AUTOSAR XML
standard types defined: uint8, uint16, uint32
package /DataTypes
  mode declaration group EcuMode: initial-mode=/DataTypes/EcuMode/RUN
    mode RUN: value=0
    mode POST_RUN: value=1
package /Interfaces
  5 x sender receiver interface:
    VehicleSpeedIf
      data VehicleSpeed: type=/DataTypes/uint16, init-value=0
    AmbientLightIf
      data AmbientLight: type=/DataTypes/uint8, init-value=255
    HeadlightCmdIf
      data HeadlightCmd: type=/DataTypes/uint8, init-value=0
    HeadlightStatusIf
      data HeadlightStatus: type=/DataTypes/uint8, init-value=0
    OdometerDistanceIf
      data Distance: type=/DataTypes/uint32, init-value=0
  client server interface WheelSpeedIf
    operation GetWheelSpeed
      arg Raw: type=/DataTypes/uint16, direction=OUT
  client server interface LightHwIf
    operation SetHeadlight
      arg State: type=/DataTypes/uint8, direction=IN
  client server interface OdometerIf
    operation UpdateSpeed
      arg Speed: type=/DataTypes/uint16, direction=IN
    operation GetDistance
      arg Distance: type=/DataTypes/uint32, direction=OUT
  mode switch interface EcuModeIf
    mode group EcuMode: type=/DataTypes/EcuMode
package /ComponentTypes
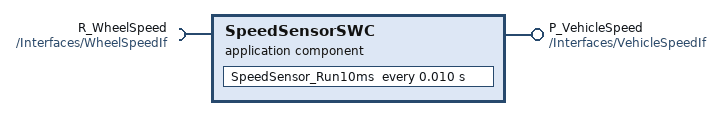
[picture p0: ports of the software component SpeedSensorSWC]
  application sw component type SpeedSensorSWC
    require port R_WheelSpeed: required-interface=/Interfaces/WheelSpeedIf
    provide port P_VehicleSpeed: provided-interface=/Interfaces/VehicleSpeedIf
    behavior SpeedSensorSWC_IB
      per instance memory SpeedSensor_State: type=SpeedSensor_StateType, field{name=calls, type=uint32}, init-value={0}
      runnable SpeedSensor_Run10ms
        data-write-access:
          access wr_VehicleSpeed: port=P_VehicleSpeed, data-element=VehicleSpeed
        sync call call_GetWheelSpeed: port=R_WheelSpeed, operation=GetWheelSpeed, timeout=0
      timing event TE_SpeedSensor_10ms: start-on-event=SpeedSensor_Run10ms, period=0.010
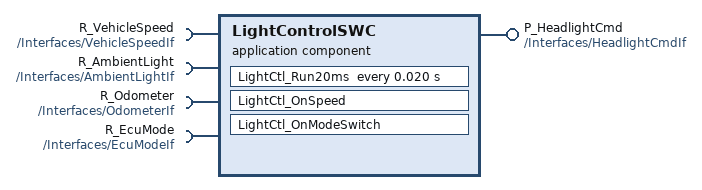
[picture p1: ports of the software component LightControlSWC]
  application sw component type LightControlSWC
    require port R_VehicleSpeed: required-interface=/Interfaces/VehicleSpeedIf
    require port R_AmbientLight: required-interface=/Interfaces/AmbientLightIf
    provide port P_HeadlightCmd: provided-interface=/Interfaces/HeadlightCmdIf
    require port R_Odometer: required-interface=/Interfaces/OdometerIf
    require port R_EcuMode: required-interface=/Interfaces/EcuModeIf
    behavior LightControlSWC_IB
      per instance memory LightCtl_State: type=LightCtl_StateType, init-value={0,0,0,0,255}
        fields:
          name=lastSpeed, type=uint16
          name=lastCmd, type=uint8
          name=postRun, type=uint8
          name=speedRxCount, type=uint32
          name=lastAmbient, type=uint8
      runnable LightCtl_Run20ms
        data-receive-point-by-arguments:
          access rd_AmbientLight: port=R_AmbientLight, data-element=AmbientLight
        data-send-points:
          access wr_HeadlightCmd: port=P_HeadlightCmd, data-element=HeadlightCmd
        mode access point mode_EcuMode: port=R_EcuMode, mode-group=EcuMode
      runnable LightCtl_OnSpeed
        data-read-access:
          access ird_VehicleSpeed: port=R_VehicleSpeed, data-element=VehicleSpeed
        sync call call_UpdateSpeed: port=R_Odometer, operation=UpdateSpeed, timeout=0
      runnable LightCtl_OnModeSwitch
        data-send-points:
          access wr_HeadlightCmd_m: port=P_HeadlightCmd, data-element=HeadlightCmd
        mode access point mode_EcuMode_m: port=R_EcuMode, mode-group=EcuMode
      timing event TE_LightCtl_20ms: start-on-event=LightCtl_Run20ms, period=0.020, disabled-mode{port=R_EcuMode, mode=/DataTypes/EcuMode/POST_RUN}
      data received event DRE_LightCtl_VehicleSpeed: start-on-event=LightCtl_OnSpeed, data={port=R_VehicleSpeed, data-element=VehicleSpeed}
      swc mode switch event MSE_LightCtl_EnterRun: start-on-event=LightCtl_OnModeSwitch, activation=ON-ENTRY, mode={port=R_EcuMode, mode=/DataTypes/EcuMode/RUN}
      swc mode switch event MSE_LightCtl_EnterPostRun: start-on-event=LightCtl_OnModeSwitch, activation=ON-ENTRY, mode={port=R_EcuMode, mode=/DataTypes/EcuMode/POST_RUN}
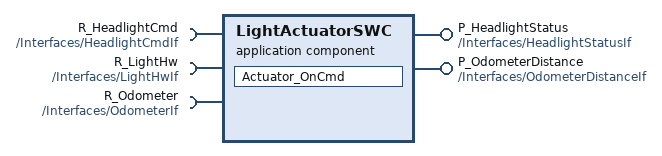
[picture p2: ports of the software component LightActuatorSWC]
  application sw component type LightActuatorSWC
    require port R_HeadlightCmd: required-interface=/Interfaces/HeadlightCmdIf
    require port R_LightHw: required-interface=/Interfaces/LightHwIf
    require port R_Odometer: required-interface=/Interfaces/OdometerIf
    provide port P_HeadlightStatus: provided-interface=/Interfaces/HeadlightStatusIf
    provide port P_OdometerDistance: provided-interface=/Interfaces/OdometerDistanceIf
    behavior LightActuatorSWC_IB
      per instance memory Actuator_State: type=Actuator_StateType, fields=[{name=lastState, type=uint8}, {name=calls, type=uint32}], init-value={255,0}
      runnable Actuator_OnCmd
        data-receive-point-by-arguments:
          access rd_HeadlightCmd: port=R_HeadlightCmd, data-element=HeadlightCmd
        data-send-points:
          access wr_HeadlightStatus: port=P_HeadlightStatus, data-element=HeadlightStatus
          access wr_Distance: port=P_OdometerDistance, data-element=Distance
        sync call call_SetHeadlight: port=R_LightHw, operation=SetHeadlight, timeout=0
        sync call call_GetDistance: port=R_Odometer, operation=GetDistance, timeout=0
      data received event DRE_Actuator_HeadlightCmd: start-on-event=Actuator_OnCmd, data={port=R_HeadlightCmd, data-element=HeadlightCmd}
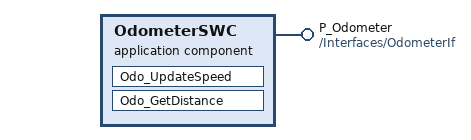
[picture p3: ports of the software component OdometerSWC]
  application sw component type OdometerSWC
    provide port P_Odometer: provided-interface=/Interfaces/OdometerIf
    behavior OdometerSWC_IB
      exclusive area EA_Odo
      per instance memory Odo_State: type=Odo_StateType, fields=[{name=distanceMm, type=uint32}, {name=updates, type=uint32}], init-value={0,0}
      runnable Odo_UpdateSpeed: can-be-invoked-concurrently=true, can-enter-exclusive-area=EA_Odo
      runnable Odo_GetDistance: can-be-invoked-concurrently=true, can-enter-exclusive-area=EA_Odo
      operation invoked event OIE_Odo_UpdateSpeed: start-on-event=Odo_UpdateSpeed, operation={port=P_Odometer, operation=UpdateSpeed}
      operation invoked event OIE_Odo_GetDistance: start-on-event=Odo_GetDistance, operation={port=P_Odometer, operation=GetDistance}
  service sw component type BswM_Service
    provide port P_EcuMode: provided-interface=/Interfaces/EcuModeIf
